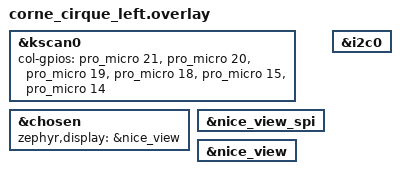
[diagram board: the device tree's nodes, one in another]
/*
 * Copyright (c) 2020 Pete Johanson
 *
 * SPDX-License-Identifier: MIT
 */
 #include <dt-bindings/zmk/matrix_transform.h>
#include "corne_cirque.dtsi"

&kscan0 {
    col-gpios
        = <&pro_micro 21 GPIO_ACTIVE_HIGH>
        , <&pro_micro 20 GPIO_ACTIVE_HIGH>
        , <&pro_micro 19 GPIO_ACTIVE_HIGH>
        , <&pro_micro 18 GPIO_ACTIVE_HIGH>
        , <&pro_micro 15 GPIO_ACTIVE_HIGH>
        , <&pro_micro 14 GPIO_ACTIVE_HIGH>
        ;
};

&chosen {
  zephyr,display = &nice_view;
};

// nice view bus
&nice_view_spi {
  status = "okay";
};

&nice_view {
  status = "okay";
};

&i2c0 {
  status = "okay";
};

/* glidepoint/virtual-input removed on left side */
